# R7FA2L209 register map
Vendor: Renesas Electronics Corporation; Series: RA2; File version: 1.10.02
CPU: CM23 r1p0, little endian, MPU, no FPU, VTOR, 2 interrupt priority bits, 32 interrupts
Registers are 8-bit, read-write, reset 0x0 unless marked. A register's access mark holds for its fields unless they carry their own. Offsets are from the block's base; [hi:lo] are bit positions; {n}, {i} and the like mark numbered series; 'fields as' and 'values as' point back to an identical list.

## ELC — Event Link Controller
Base 0x40041000
0x00 ELCR — Event Link Controller Register
  [7] ELCON — All Event Link Enable
    0=ELC function is disabled; 1=ELC function is enabled
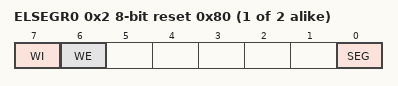
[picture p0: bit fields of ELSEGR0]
{0x2+2i} ELSEGR{i} (i=0..1) reset 0x80 — Event Link Software Event Generation Register {i}
  [7] WI wo — ELSEGR Register Write Disable
    0=Write to ELSEGR register enabled; 1=Write to ELSEGR register disabled
  [6] WE — SEG Bit Write Enable
    0=Write to SEG bit disabled; 1=Write to SEG bit enabled
  [0] SEG wo — Software Event Generation
    0=Normal operation; 1=Software event is generated
{0x10+4i} ELSR{i} (i=0..3) 16-bit — Event Link Setting Register {i}
  [7:0] ELS — Event Link Select
{0x10+4i} ELSR{i} (i=8..9) 16-bit — Event Link Setting Register {i}
  [7:0] ELS — Event Link Select
0x40 ELSR12 16-bit — Event Link Setting Register 12
  [7:0] ELS — Event Link Select
{0x10+4i} ELSR{i} (i=14..15) 16-bit — Event Link Setting Register {i}
  [7:0] ELS — Event Link Select
0x58 ELSR18 16-bit — Event Link Setting Register 18
  [7:0] ELS — Event Link Select

## POEG — Port Output Enable Module for GPT
Base 0x40042000
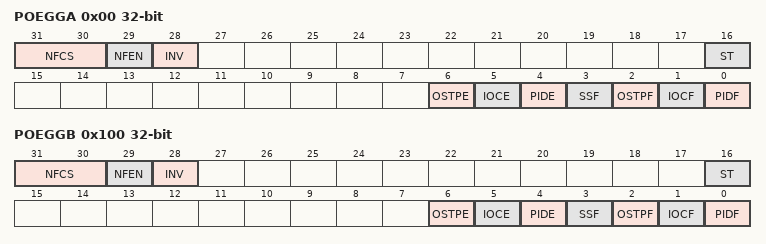
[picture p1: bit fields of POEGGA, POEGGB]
0x00 POEGGA 32-bit — POEG Group A Setting Register
  [31:30] NFCS — Noise Filter Clock Select
    0=Sample GTETRGn pin input level three times every PCLKB; 1=Sample GTETRGn pin input level three times every PCLKB/8; 2=Sample GTETRGn pin input level three times every PCLKB/32; 3=Sample GTETRGn pin input level three times every PCLKB/128
  [29] NFEN — Noise Filter Enable
    0=Disable noise filtering; 1=Enable noise filtering
  [28] INV — GTETRGA Input Reverse
    0=Input GTETRGn as-is; 1=Input GTETRGn in reverse
  [16] ST ro — GTETRGA Input Status Flag
    0=GTETRGn input after filtering was 0; 1=GTETRGn input after filtering was 1
  [6] OSTPE — Oscillation Stop Detection Enable
    0=Disable output-disable requests from oscillation stop detection; 1=Enable output-disable requests from oscillation stop detection
  [5] IOCE — Enable for GPT Output-Disable Request
    0=Disable output-disable requests from GPT; 1=Enable output-disable requests from GPT
  [4] PIDE — Port Input Detection Enable
    0=Disable output-disable requests from the GTETRGn pins; 1=Enable output-disable requests from the GTETRGn pins
  [3] SSF — Software Stop Flag
    0=No output-disable request from software occurred; 1=Output-disable request from software occurred
  [2] OSTPF — Oscillation Stop Detection Flag
    0=No output-disable request from oscillation stop detection occurred; 1=Output-disable request from oscillation stop detection occurred
  [1] IOCF — Detection Flag for GPT Output-Disable Request
    0=No output-disable request from GPT occurred; 1=Output-disable request from GPT occurred
  [0] PIDF — Port Input Detection Flag
    0=No output-disable request from the GTETRGn pin occurred; 1=Output-disable request from the GTETRGn pin occurred
0x100 POEGGB 32-bit — POEG Group B Setting Register
  [31:30] NFCS — Noise Filter Clock Select
    values as POEGGA.NFCS
  [29] NFEN — Noise Filter Enable
    0=Disable noise filtering; 1=Enable noise filtering
  [28] INV — GTETRGB Input Reverse
    0=Input GTETRGn as-is; 1=Input GTETRGn in reverse
  [16] ST ro — GTETRGB Input Status Flag
    values as POEGGA.ST
  [6] OSTPE — Oscillation Stop Detection Enable
    values as POEGGA.OSTPE
  [5] IOCE — Enable for GPT Output-Disable Request
    values as POEGGA.IOCE
  [4] PIDE — Port Input Detection Enable
    values as POEGGA.PIDE
  [3] SSF — Software Stop Flag
    values as POEGGA.SSF
  [2] OSTPF — Oscillation Stop Detection Flag
    values as POEGGA.OSTPF
  [1] IOCF — Detection Flag for GPT Output-Disable Request
    values as POEGGA.IOCF
  [0] PIDF — Port Input Detection Flag
    values as POEGGA.PIDF
